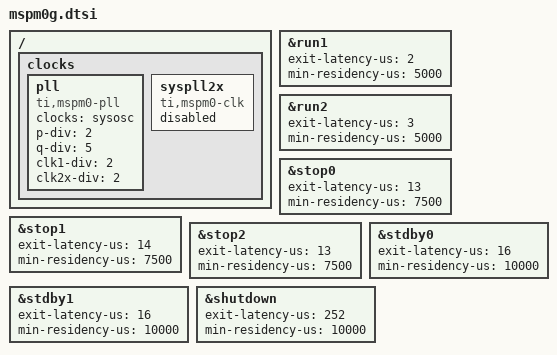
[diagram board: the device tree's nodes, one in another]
/*
 * Copyright (c) 2025 Texas Instruments
 * Copyright (c) 2025 Linumiz
 *
 * SPDX-License-Identifier: Apache-2.0
 */

#include <ti/mspm0/mspm0.dtsi>

/{
	clocks: clocks {
		pll: pll {
			compatible = "ti,mspm0-pll";
			clocks = <&sysosc>;
			p-div = <2>;
			q-div = <5>;
			clk1-div = <2>;
			clk2x-div = <2>;
			#clock-cells = <0>;
			status = "okay";
		};

		syspll2x: syspll2x {
			#clock-cells = <1>;
			compatible = "ti,mspm0-clk";
			status = "disabled";
		};
	};
};

&run1 {
	exit-latency-us = <2>; /* 1.5us */
	min-residency-us = <5000>;
};

&run2 {
	exit-latency-us = <3>; /* 2.1us */
	min-residency-us = <5000>;
};

&stop0 {
	exit-latency-us = <13>; /* 12.1us */
	min-residency-us = <7500>;
};

&stop1 {
	exit-latency-us = <14>; /* 13.5us */
	min-residency-us = <7500>;
};

&stop2 {
	exit-latency-us = <13>; /* 12.9us */
	min-residency-us = <7500>;
};

&stdby0 {
	exit-latency-us = <16>; /* 15.2us */
	min-residency-us = <10000>;
};

&stdby1 {
	exit-latency-us = <16>; /* 15.2us */
	min-residency-us = <10000>;
};

&shutdown {
	exit-latency-us = <252>; /* 252us */
	min-residency-us = <10000>;
};
